# STM32U5F9 register map
File version: 1.1
CPU: CM33 r0p1, little endian, MPU, FPU, 4 interrupt priority bits
Registers are 32-bit, read-write, reset 0x0 unless marked. A register's access mark holds for its fields unless they carry their own. Offsets are from the block's base; [hi:lo] are bit positions; {n}, {i} and the like mark numbered series; 'fields as' and 'values as' point back to an identical list.

## FMC
Base 0x420D0400
Same registers: SEC_FMC 0x520D0400
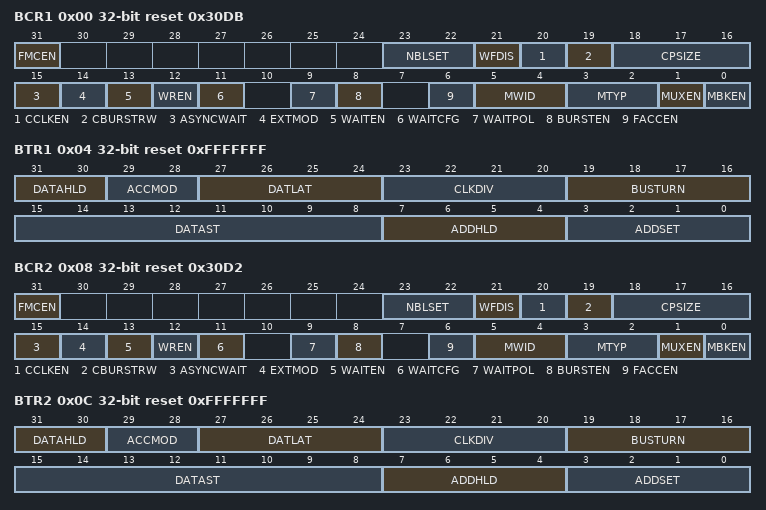
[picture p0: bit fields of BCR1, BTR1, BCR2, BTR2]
0x00 BCR1 reset 0x30DB — SRAM/NOR-Flash chip-select control register for bank 1
  [31] FMCEN — FMC controller enable
  [23:22] NBLSET — Byte lane (NBL) setup
  [21] WFDIS — Write FIFO disable
  [20] CCLKEN — Continuous clock enable
  [19] CBURSTRW — Write burst enable
  [18:16] CPSIZE — CRAM Page Size
  [15] ASYNCWAIT — Wait signal during asynchronous
  [14] EXTMOD — Extended mode enable
  [13] WAITEN — Wait enable bit
  [12] WREN — Write enable bit
  [11] WAITCFG — Wait timing configuration
  [9] WAITPOL — Wait signal polarity bit
  [8] BURSTEN — Burst enable bit
  [6] FACCEN — Flash access enable
  [5:4] MWID — Memory data bus width
  [3:2] MTYP — Memory type
  [1] MUXEN — Address/data multiplexing enable bit
  [0] MBKEN — Memory bank enable bit
0x04 BTR1 reset 0xFFFFFFF — SRAM/NOR-Flash chip-select timing register for bank 1
  [31:30] DATAHLD — Data hold phase duration
  [29:28] ACCMOD — Access mode
  [27:24] DATLAT — Data latency for synchronous memory
  [23:20] CLKDIV — Clock divide ratio (for FMC_CLK signal)
  [19:16] BUSTURN — Bus turnaround phase duration
  [15:8] DATAST — Data-phase duration
  [7:4] ADDHLD — Address-hold phase duration
  [3:0] ADDSET — Address setup phase duration
0x08 BCR2 reset 0x30D2 — SRAM/NOR-Flash chip-select control register for bank 2
  fields as BCR1
0x0C BTR2 reset 0xFFFFFFF — SRAM/NOR-Flash chip-select timing register for bank 2
  fields as BTR1
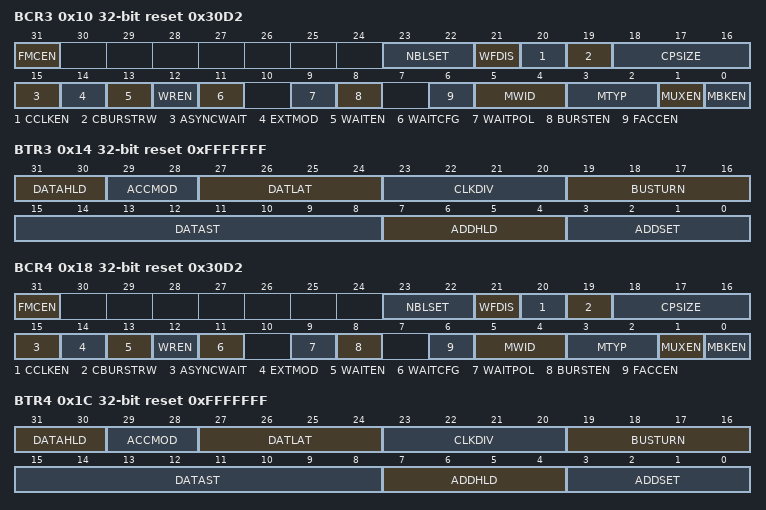
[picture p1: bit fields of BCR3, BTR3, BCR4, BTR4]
0x10 BCR3 reset 0x30D2 — SRAM/NOR-Flash chip-select control register for bank 3
  fields as BCR1
0x14 BTR3 reset 0xFFFFFFF — SRAM/NOR-Flash chip-select timing register for bank 3
  fields as BTR1
0x18 BCR4 reset 0x30D2 — SRAM/NOR-Flash chip-select control register for bank 4
  fields as BCR1
0x1C BTR4 reset 0xFFFFFFF — SRAM/NOR-Flash chip-select timing register for bank 4
  fields as BTR1
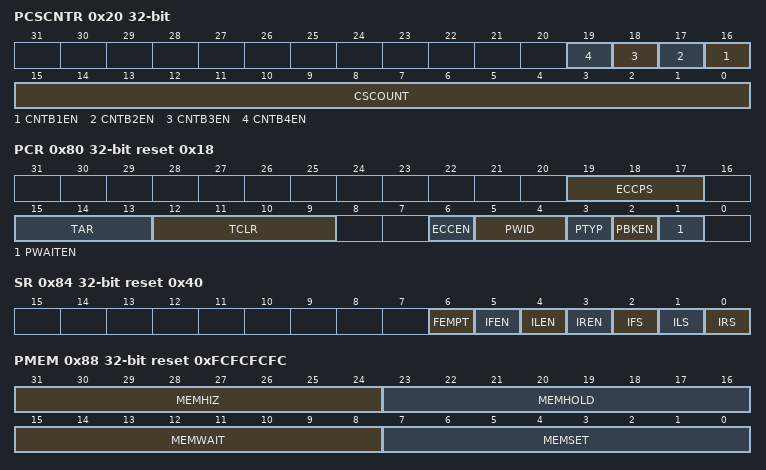
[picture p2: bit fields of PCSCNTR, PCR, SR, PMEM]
0x20 PCSCNTR — PSRAM chip select counter register
  [n+15] CNTB{n}EN (n=1..4) — Counter Bank {n} enable
  [15:0] CSCOUNT — Chip select counter
0x80 PCR reset 0x18 — NAND Flash control registers
  [19:17] ECCPS — ECC page size
  [15:13] TAR — ALE to RE delay
  [12:9] TCLR — CLE to RE delay
  [6] ECCEN — ECC computation logic enable bit
  [5:4] PWID — Data bus width
  [3] PTYP — Memory type
  [2] PBKEN — NAND Flash memory bank enable bit
  [1] PWAITEN — Wait feature enable bit
0x84 SR access per field reset 0x40 — status and interrupt register
  [6] FEMPT ro — FIFO empty. Read-only bit that provides
  [5] IFEN rw — Interrupt falling edge detection enable
  [4] ILEN rw — Interrupt high-level detection enable
  [3] IREN rw — Interrupt rising edge detection enable
  [2] IFS rw — Interrupt falling edge status The flag
  [1] ILS rw — Interrupt high-level status The flag is
  [0] IRS rw — Interrupt rising edge status The flag is
0x88 PMEM reset 0xFCFCFCFC — Common memory space timing register
  [31:24] MEMHIZ — Common memory x data bus Hi-Z time These
  [23:16] MEMHOLD — Common memory hold time These bits
  [15:8] MEMWAIT — Common memory wait time These bits
  [7:0] MEMSET — Common memory x setup time These bits
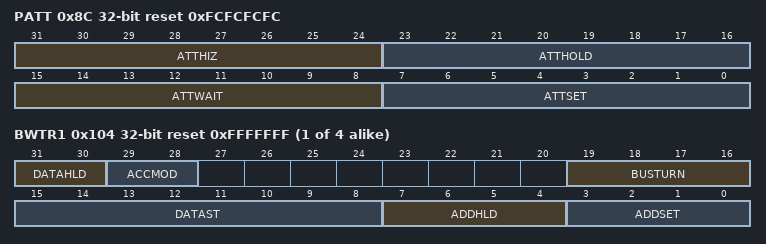
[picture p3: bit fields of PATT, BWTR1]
0x8C PATT reset 0xFCFCFCFC — The FMC_PATT read/write register contains
  [31:24] ATTHIZ — Attribute memory data bus Hi-Z time
  [23:16] ATTHOLD — Attribute memory hold time These bits
  [15:8] ATTWAIT — Attribute memory wait time These bits
  [7:0] ATTSET — Attribute memory setup time These bits
0x94 ECCR ro — This register contain the current error
  [31:0] ECC — ECC result This field contains the value
{0xFC+8i} BWTR{i} reset 0xFFFFFFF (i=1..4) — SRAM/NOR-Flash write timing registers {i}
  [31:30] DATAHLD — Data hold phase duration
  [29:28] ACCMOD — Access mode
  [19:16] BUSTURN — Bus turnaround phase duration
  [15:8] DATAST — Data-phase duration
  [7:4] ADDHLD — Address-hold phase duration
  [3:0] ADDSET — Address setup phase duration
